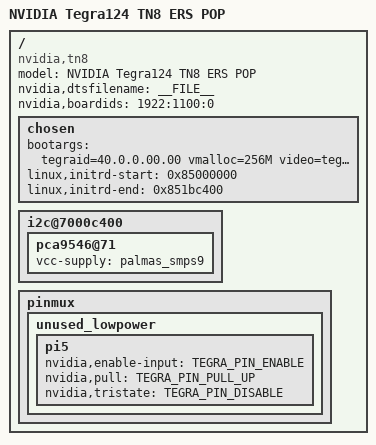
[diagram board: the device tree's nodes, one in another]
/dts-v1/;

#include "tegra124-tn8.dtsi"
#include "tegra124-platforms/tegra124-tn8-dfll.dtsi"
#include "tegra124-platforms/tegra124-tn8-emc-e1922-1100-a00.dtsi"
#include "tegra124-platforms/tegra124-ardbeg-powermon-e1780-1000-a01.dtsi"
#include "tegra124-platforms/tegra124-tn8-pmic-e1936-1000-a00.dtsi"
#include "tegra124-platforms/tegra124-tn8-fixed-e1936-1000-a00.dtsi"
#include "tegra124-platforms/tegra124-tn8-sensor-p1761-1470-a00.dtsi"
#include "tegra124-platforms/tegra124-tn8-pinmux-p1761-1470-a00.dtsi"
#include "tegra124-platforms/tegra124-tn8-gpio-p1761-1470-a00.dtsi"
#include "tegra124-platforms/tegra124-tn8-keys-e1780-1100-a02.dtsi"
#include "tegra124-platforms/tegra124-tn8-camera-e1780-a00.dtsi"

/ {
	model = "NVIDIA Tegra124 TN8 ERS POP";
	compatible = "nvidia,tn8", "nvidia,tegra124";
	nvidia,dtsfilename = __FILE__;
	nvidia,boardids = "1922:1100:0";
	#address-cells = <2>;
	#size-cells = <2>;

	chosen {
		bootargs = "tegraid=40.0.0.00.00 vmalloc=256M video=tegrafb console=ttyS0,115200n8 earlyprintk";
		linux,initrd-start = <0x85000000>;
		linux,initrd-end = <0x851bc400>;
	};

	i2c@7000c400 {
		pca9546@71 {
			vcc-supply = <&palmas_smps9>;
		};
	};

	pinmux {
		unused_lowpower {
			pi5 {
				nvidia,enable-input = <TEGRA_PIN_ENABLE>;
				nvidia,pull = <TEGRA_PIN_PULL_UP>;
				nvidia,tristate = <TEGRA_PIN_DISABLE>;
			};
		};
	};
};

